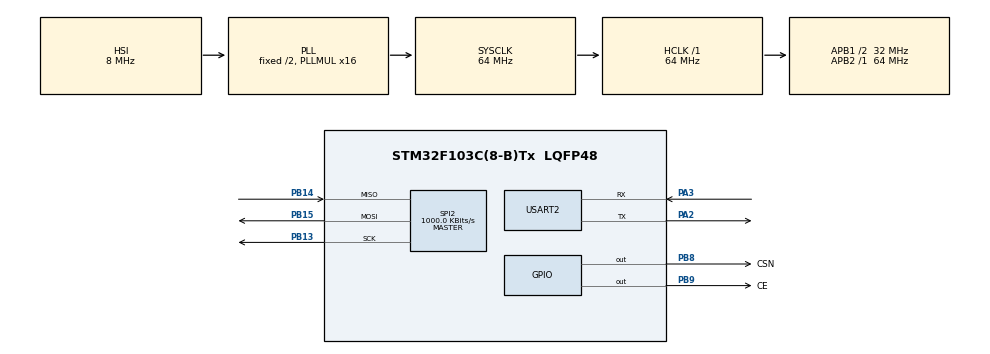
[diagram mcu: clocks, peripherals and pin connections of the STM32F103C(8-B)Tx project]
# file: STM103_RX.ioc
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Mcu.Family=STM32F1
Mcu.Name=STM32F103C(8-B)Tx
Mcu.Package=LQFP48
NVIC.PriorityGroup=NVIC_PRIORITYGROUP_4
PA13.Mode=Serial_Wire
PA13.Signal=SYS_JTMS-SWDIO
PA14.Mode=Serial_Wire
PA14.Signal=SYS_JTCK-SWCLK
PA2.Mode=Asynchronous
PA2.Signal=USART2_TX
PA3.Mode=Asynchronous
PA3.Signal=USART2_RX
PB13.Mode=Full_Duplex_Master
PB13.Signal=SPI2_SCK
PB14.Mode=Full_Duplex_Master
PB14.Signal=SPI2_MISO
PB15.Mode=Full_Duplex_Master
PB15.Signal=SPI2_MOSI
PB8.GPIO_Label=CSN
PB8.Signal=GPIO_Output
PB9.GPIO_Label=CE
PB9.Signal=GPIO_Output
ProjectManager.HeapSize=0x200
ProjectManager.StackSize=0x400
ProjectManager.TargetToolchain=TrueSTUDIO
RCC.AHBFreq_Value=64000000
RCC.APB1CLKDivider=RCC_HCLK_DIV2
RCC.APB1Freq_Value=32000000
RCC.APB1TimFreq_Value=64000000
RCC.APB2Freq_Value=64000000
RCC.APB2TimFreq_Value=64000000
RCC.HCLKFreq_Value=64000000
RCC.PLLMUL=RCC_PLL_MUL16
RCC.SYSCLKFreq_VALUE=64000000
RCC.SYSCLKSource=RCC_SYSCLKSOURCE_PLLCLK
RCC.USBFreq_Value=64000000
SPI2.BaudRatePrescaler=SPI_BAUDRATEPRESCALER_32
SPI2.CalculateBaudRate=1000.0 KBits/s
SPI2.Direction=SPI_DIRECTION_2LINES
SPI2.Mode=SPI_MODE_MASTER
SPI2.VirtualType=VM_MASTER
USART2.VirtualMode=VM_ASYNC
board=custom

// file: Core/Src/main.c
/* USER CODE BEGIN Header */
/**
  ******************************************************************************
  * @file           : main.c
  * @brief          : Main program body
  ******************************************************************************
  * @attention
  *
  * <h2><center>&copy; Copyright (c) 2021 STMicroelectronics.
  * All rights reserved.</center></h2>
  *
  * This software component is licensed by ST under BSD 3-Clause license,
  * the "License"; You may not use this file except in compliance with the
  * License. You may obtain a copy of the License at:
  *                        opensource.org/licenses/BSD-3-Clause
  *
  ******************************************************************************
  */
/* USER CODE END Header */
#include "main.h"
#include "stm32f1xx_hal.h"
#include "MY_NRF24.h"

SPI_HandleTypeDef hspi2;

UART_HandleTypeDef huart2;

void SystemClock_Config(void);
static void MX_GPIO_Init(void);
static void MX_USART2_UART_Init(void);
static void MX_SPI2_Init(void);

/* USER CODE BEGIN 0 */
uint64_t TxpipeAddrs = 0x11223344AA;
char myTxData[32]= "Merhaba";
/* USER CODE END 0 */

int main(void)
{

  /* MCU Configuration--------------------------------------------------------*/

  /* Reset of all peripherals, Initializes the Flash interface and the Systick. */
  HAL_Init();

  /* Configure the system clock */
  SystemClock_Config();

  /* Initialize all configured peripherals */
  MX_GPIO_Init();
  MX_USART2_UART_Init();
  MX_SPI2_Init();
  /* USER CODE BEGIN 2 */

  NRF24_begin(CSN_GPIO_Port,GPIO_PIN_9,GPIO_PIN_8,hspi2);
  nrf24_DebugUART_Init(huart2);

  printRadioSettings();

  NRF24_stopListening();
  NRF24_openWritingPipe(TxpipeAddrs);
  NRF24_setAutoAck(1);
  NRF24_setChannel(52);
  NRF24_setPayloadSize(32);
  /* USER CODE END 2 */

  /* Infinite loop */
  while (1)
  {

    /* USER CODE BEGIN 3 */
	  if(NRF24_write(myTxData,32))
	  {
	 	 {
	 		 HAL_UART_Transmit(&huart2,(uint8_t *)"Transmitted Successfully\r\n",strlen("Transmitted Successfully\r\n"),10);
	 	 }
	 	  HAL_Delay(1000);
	   }

  }
  /* USER CODE END 3 */
}

void SystemClock_Config(void)
{
  RCC_OscInitTypeDef RCC_OscInitStruct = {0};
  RCC_ClkInitTypeDef RCC_ClkInitStruct = {0};

  /** Initializes the RCC Oscillators according to the specified parameters
  * in the RCC_OscInitTypeDef structure.
  */
  RCC_OscInitStruct.OscillatorType = RCC_OSCILLATORTYPE_HSI;
  RCC_OscInitStruct.HSIState = RCC_HSI_ON;
  RCC_OscInitStruct.HSICalibrationValue = RCC_HSICALIBRATION_DEFAULT;
  RCC_OscInitStruct.PLL.PLLState = RCC_PLL_ON;
  RCC_OscInitStruct.PLL.PLLSource = RCC_PLLSOURCE_HSI_DIV2;
  RCC_OscInitStruct.PLL.PLLMUL = RCC_PLL_MUL16;
  if (HAL_RCC_OscConfig(&RCC_OscInitStruct) != HAL_OK)
  {
    Error_Handler();
  }
  /** Initializes the CPU, AHB and APB buses clocks
  */
  RCC_ClkInitStruct.ClockType = RCC_CLOCKTYPE_HCLK|RCC_CLOCKTYPE_SYSCLK
                              |RCC_CLOCKTYPE_PCLK1|RCC_CLOCKTYPE_PCLK2;
  RCC_ClkInitStruct.SYSCLKSource = RCC_SYSCLKSOURCE_PLLCLK;
  RCC_ClkInitStruct.AHBCLKDivider = RCC_SYSCLK_DIV1;
  RCC_ClkInitStruct.APB1CLKDivider = RCC_HCLK_DIV2;
  RCC_ClkInitStruct.APB2CLKDivider = RCC_HCLK_DIV1;

  if (HAL_RCC_ClockConfig(&RCC_ClkInitStruct, FLASH_LATENCY_2) != HAL_OK)
  {
    Error_Handler();
  }
}

static void MX_SPI2_Init(void)
{

  /* SPI2 parameter configuration*/
  hspi2.Instance = SPI2;
  hspi2.Init.Mode = SPI_MODE_MASTER;
  hspi2.Init.Direction = SPI_DIRECTION_2LINES;
  hspi2.Init.DataSize = SPI_DATASIZE_8BIT;
  hspi2.Init.CLKPolarity = SPI_POLARITY_LOW;
  hspi2.Init.CLKPhase = SPI_PHASE_1EDGE;
  hspi2.Init.NSS = SPI_NSS_SOFT;
  hspi2.Init.BaudRatePrescaler = SPI_BAUDRATEPRESCALER_32;
  hspi2.Init.FirstBit = SPI_FIRSTBIT_MSB;
  hspi2.Init.TIMode = SPI_TIMODE_DISABLE;
  hspi2.Init.CRCCalculation = SPI_CRCCALCULATION_DISABLE;
  hspi2.Init.CRCPolynomial = 10;
  if (HAL_SPI_Init(&hspi2) != HAL_OK)
  {
    Error_Handler();
  }

}

static void MX_USART2_UART_Init(void)
{

  huart2.Instance = USART2;
  huart2.Init.BaudRate = 115200;
  huart2.Init.WordLength = UART_WORDLENGTH_8B;
  huart2.Init.StopBits = UART_STOPBITS_1;
  huart2.Init.Parity = UART_PARITY_NONE;
  huart2.Init.Mode = UART_MODE_TX_RX;
  huart2.Init.HwFlowCtl = UART_HWCONTROL_NONE;
  huart2.Init.OverSampling = UART_OVERSAMPLING_16;
  if (HAL_UART_Init(&huart2) != HAL_OK)
  {
    Error_Handler();
  }

}

static void MX_GPIO_Init(void)
{
  GPIO_InitTypeDef GPIO_InitStruct = {0};

  /* GPIO Ports Clock Enable */
  __HAL_RCC_GPIOA_CLK_ENABLE();
  __HAL_RCC_GPIOB_CLK_ENABLE();

  /*Configure GPIO pin Output Level */
  HAL_GPIO_WritePin(GPIOB, CSN_Pin|CE_Pin, GPIO_PIN_RESET);

  /*Configure GPIO pins : CSN_Pin CE_Pin */
  GPIO_InitStruct.Pin = CSN_Pin|CE_Pin;
  GPIO_InitStruct.Mode = GPIO_MODE_OUTPUT_PP;
  GPIO_InitStruct.Pull = GPIO_NOPULL;
  GPIO_InitStruct.Speed = GPIO_SPEED_FREQ_LOW;
  HAL_GPIO_Init(GPIOB, &GPIO_InitStruct);

}

void Error_Handler(void)
{
  __disable_irq();
  while (1)
  {
  }
}

/************************ (C) COPYRIGHT STMicroelectronics *****END OF FILE****/
